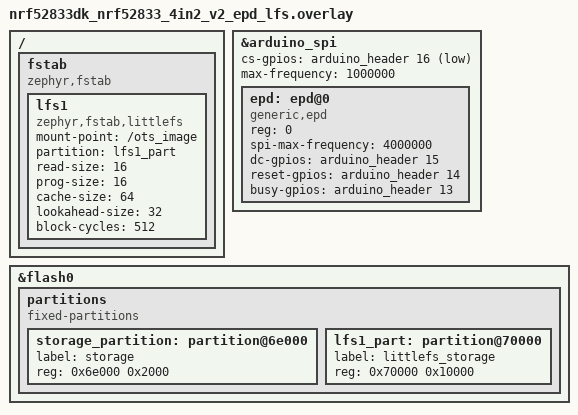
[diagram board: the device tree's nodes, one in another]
/*
 * Copyright (c) 2023 Nordic Semiconductor ASA
 *
 * SPDX-License-Identifier: Apache-2.0
 */

 &arduino_spi {
	cs-gpios = <&arduino_header 16 GPIO_ACTIVE_LOW>; /* D10 */
	status="okay";
	max-frequency = < 1000000 >;

	epd: epd@0 {
		compatible = "generic,epd";
		reg = <0>;
		status = "okay";
		spi-max-frequency = <4000000>;
		dc-gpios = <&arduino_header 15 GPIO_ACTIVE_HIGH>;        /* D9 EPD driver use raw instead of logical level */
		reset-gpios = <&arduino_header 14 GPIO_ACTIVE_HIGH>;     /* D8 EPD driver use raw instead of logical level */
		busy-gpios = <&arduino_header 13 GPIO_ACTIVE_HIGH>;      /* D7 EPD driver use raw instead of logical level */
	};
 };

/delete-node/ &storage_partition;
/ {
	fstab {
		compatible = "zephyr,fstab";
		lfs1: lfs1 {
			compatible = "zephyr,fstab,littlefs";
			mount-point = "/ots_image";
			partition = <&lfs1_part>;
			read-size = <16>;
			prog-size = <16>;
			cache-size = <64>;
			lookahead-size = <32>;
			block-cycles = <512>;
		};
	};
};


&flash0 {
	partitions {
		compatible = "fixed-partitions";
		#address-cells = <1>;
		#size-cells = <1>;
		storage_partition: partition@6e000 {
			label = "storage";
			reg = <0x6e000 0x2000>;
		};
		lfs1_part: partition@70000 {
			label = "littlefs_storage";
			reg = <0x70000 0x10000>;
		};
	};
};
